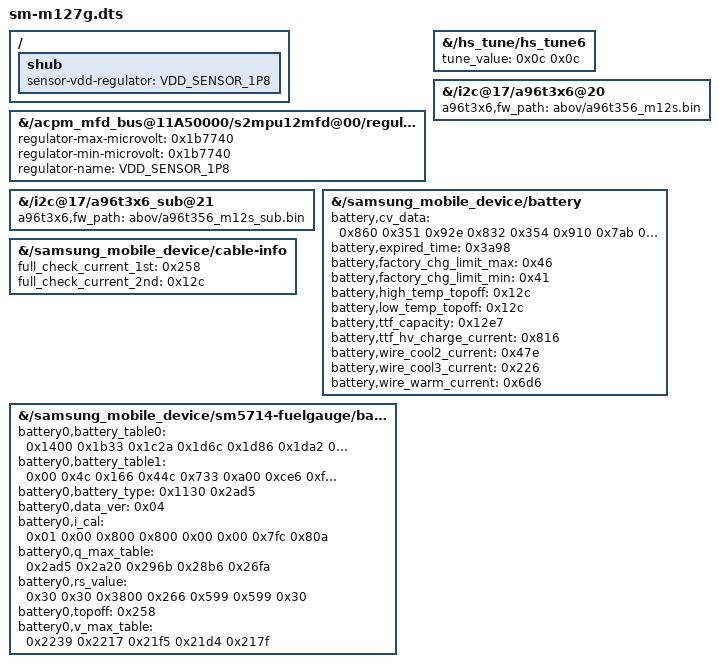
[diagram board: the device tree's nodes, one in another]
// SPDX-License-Identifier: GPL-2.0
/*
 * SM-M127G board data, from the stock DTBO
 *
 * Copyright (c) 2021 Samsung Electronics Co., Ltd.
 */

/dts-v1/;
/plugin/;

/ {
	fragment@0 {
		target-path = "/acpm_mfd_bus@11A50000/s2mpu12mfd@00/regulators/LDO30";
		__overlay__ {
			regulator-max-microvolt = <0x1b7740>;
			regulator-min-microvolt = <0x1b7740>;
			regulator-name = "VDD_SENSOR_1P8";
		};
	};

	fragment@1 {
		target-path = "/hs_tune/hs_tune6";
		__overlay__ {
			tune_value = <0x0c 0x0c>;
		};
	};

	fragment@2 {
		target-path = "/i2c@17/a96t3x6@20";
		__overlay__ {
			a96t3x6,fw_path = "abov/a96t356_m12s.bin";
		};
	};

	fragment@3 {
		target-path = "/i2c@17/a96t3x6_sub@21";
		__overlay__ {
			a96t3x6,fw_path = "abov/a96t356_m12s_sub.bin";
		};
	};

	fragment@4 {
		target-path = "/samsung_mobile_device/battery";
		__overlay__ {
			battery,cv_data = <0x860 0x351 0x92e 0x832 0x354 0x910 0x7ab 0x35d 0x8b5 0x733 0x366 0x85b 0x67e 0x370 0x7e2 0x5ef 0x37a 0x76a 0x540 0x385 0x6d4 0x4be 0x38f 0x63d 0x402 0x399 0x588 0x3b4 0x3a2 0x4d4 0x31c 0x3ac 0x400 0x29e 0x3b6 0x2f1 0x233 0x3c0 0x200 0x220 0x3ca 0x187 0x1ed 0x3d4 0x10f 0x1ba 0x3df 0x78 0x1ad 0x3e6 0x1e 0x19c 0x3e8 0x00>;
			battery,expired_time = <0x3a98>;
			battery,factory_chg_limit_max = <0x46>;
			battery,factory_chg_limit_min = <0x41>;
			battery,high_temp_topoff = <0x12c>;
			battery,low_temp_topoff = <0x12c>;
			battery,ttf_capacity = <0x12e7>;
			battery,ttf_hv_charge_current = <0x816>;
			battery,wire_cool2_current = <0x47e>;
			battery,wire_cool3_current = <0x226>;
			battery,wire_warm_current = <0x6d6>;
		};
	};

	fragment@5 {
		target-path = "/samsung_mobile_device/cable-info";
		__overlay__ {
			full_check_current_1st = <0x258>;
			full_check_current_2nd = <0x12c>;
		};
	};

	fragment@6 {
		target-path = "/samsung_mobile_device/sm5714-fuelgauge/battery_params";
		__overlay__ {
			battery0,battery_table0 = <0x1400 0x1b33 0x1c2a 0x1d6c 0x1d86 0x1da2 0x1dbb 0x1ddb 0x1df0 0x1e30 0x1e4f 0x1e5d 0x1e7e 0x1ea7 0x1edc 0x1f3d 0x1f6f 0x1fa0 0x1ff1 0x2050 0x2082 0x20ee 0x2239 0x2400>;
			battery0,battery_table1 = <0x00 0x4c 0x166 0x44c 0x733 0xa00 0xce6 0xfcc 0x1299 0x1b33 0x2100 0x23cc 0x2980 0x2f4c 0x3500 0x3ab3 0x3d99 0x4080 0x4633 0x4be6 0x4ecc 0x5480 0x6400 0x6419>;
			battery0,battery_type = <0x1130 0x2ad5>;
			battery0,data_ver = <0x04>;
			battery0,i_cal = <0x01 0x00 0x800 0x800 0x00 0x00 0x7fc 0x80a>;
			battery0,q_max_table = <0x2ad5 0x2a20 0x296b 0x28b6 0x26fa>;
			battery0,rs_value = <0x30 0x30 0x3800 0x266 0x599 0x599 0x30>;
			battery0,topoff = <0x258>;
			battery0,v_max_table = <0x2239 0x2217 0x21f5 0x21d4 0x217f>;
		};
	};

	fragment@7 {
		target-path = "/";
		__overlay__ {
			shub {
				sensor-vdd-regulator = "VDD_SENSOR_1P8";
			};
		};
	};
};
